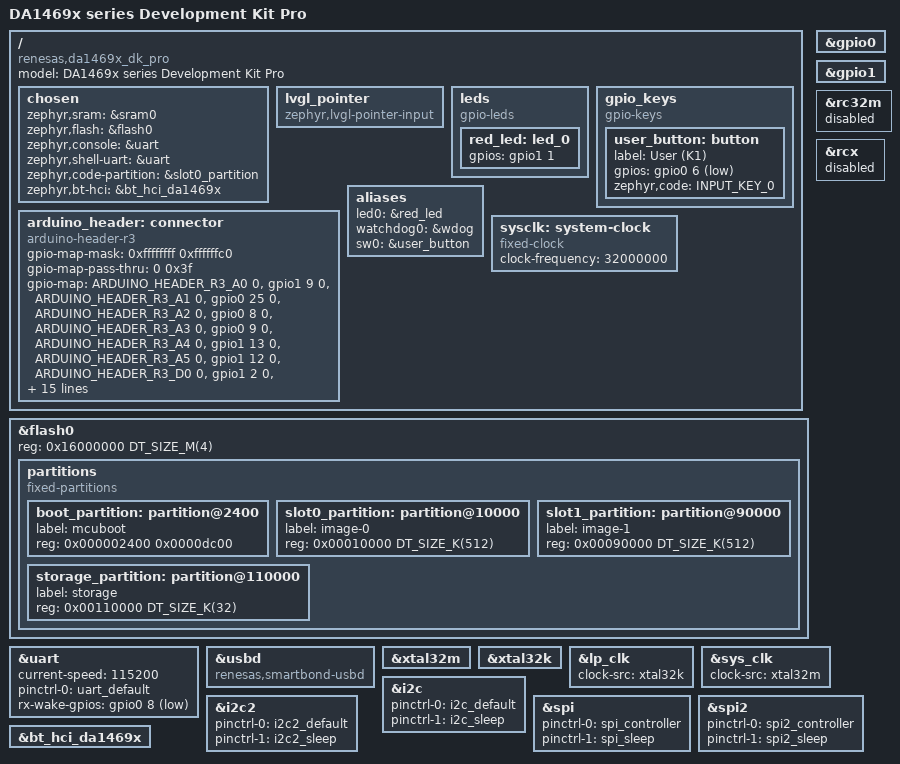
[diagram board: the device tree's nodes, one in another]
/*
 * Copyright (c) 2022 Renesas Electronics Corporation and/or its affiliates
 * SPDX-License-Identifier: Apache-2.0
 */

/dts-v1/;
#include <renesas/smartbond/da14699.dtsi>
#include "da1469x_dk_pro-pinctrl.dtsi"
#include <zephyr/dt-bindings/gpio/arduino-header-r3.h>
#include <zephyr/dt-bindings/input/input-event-codes.h>

/ {
	model = "DA1469x series Development Kit Pro";
	compatible = "renesas,da1469x_dk_pro";
	#address-cells = <1>;
	#size-cells = <1>;

	chosen {
		zephyr,sram = &sram0;
		zephyr,flash = &flash0;
		zephyr,console = &uart;
		zephyr,shell-uart = &uart;
		zephyr,code-partition = &slot0_partition;
		zephyr,bt-hci = &bt_hci_da1469x;
	};

	lvgl_pointer {
		compatible = "zephyr,lvgl-pointer-input";
	};

	leds {
		compatible = "gpio-leds";

		red_led: led_0 {
			gpios = <&gpio1 1 GPIO_ACTIVE_HIGH>;
		};
	};

	gpio_keys {
		compatible = "gpio-keys";

		user_button: button {
			label = "User (K1)";
			gpios = <&gpio0 6 (GPIO_ACTIVE_LOW | GPIO_PULL_UP)>;
			zephyr,code = <INPUT_KEY_0>;
		};
	};

	arduino_header: connector {
		compatible = "arduino-header-r3";
		#gpio-cells = <2>;
		gpio-map-mask = <0xffffffff 0xffffffc0>;
		gpio-map-pass-thru = <0 0x3f>;
		gpio-map = <ARDUINO_HEADER_R3_A0 0 &gpio1 9 0>,
			   <ARDUINO_HEADER_R3_A1 0 &gpio0 25 0>,
			   <ARDUINO_HEADER_R3_A2 0 &gpio0 8 0>,
			   <ARDUINO_HEADER_R3_A3 0 &gpio0 9 0>,
			   <ARDUINO_HEADER_R3_A4 0 &gpio1 13 0>,
			   <ARDUINO_HEADER_R3_A5 0 &gpio1 12 0>,
			   <ARDUINO_HEADER_R3_D0 0 &gpio1 2 0>,
			   <ARDUINO_HEADER_R3_D1 0 &gpio1 3 0>,
			   <ARDUINO_HEADER_R3_D2 0 &gpio1 4 0>,
			   <ARDUINO_HEADER_R3_D3 0 &gpio1 5 0>,
			   <ARDUINO_HEADER_R3_D4 0 &gpio1 7 0>,
			   <ARDUINO_HEADER_R3_D5 0 &gpio1 8 0>,
			   <ARDUINO_HEADER_R3_D6 0 &gpio0 17 0>,
			   <ARDUINO_HEADER_R3_D7 0 &gpio0 18 0>,
			   <ARDUINO_HEADER_R3_D8 0 &gpio0 19 0>,
			   <ARDUINO_HEADER_R3_D9 0 &gpio0 20 0>,
			   <ARDUINO_HEADER_R3_D10 0 &gpio0 21 0>,
			   <ARDUINO_HEADER_R3_D11 0 &gpio0 24 0>,
			   <ARDUINO_HEADER_R3_D12 0 &gpio0 26 0>,
			   <ARDUINO_HEADER_R3_D13 0 &gpio0 27 0>,
			   <ARDUINO_HEADER_R3_D14 0 &gpio0 28 0>,
			   <ARDUINO_HEADER_R3_D15 0 &gpio0 29 0>;
	};

	aliases {
		led0 = &red_led;
		watchdog0 = &wdog;
		sw0 = &user_button;
	};

	sysclk: system-clock {
		compatible = "fixed-clock";
		clock-frequency = <32000000>;
		#clock-cells = <0>;
	};
};

&flash0 {
	reg = <0x16000000 DT_SIZE_M(4)>;

	partitions {
		compatible = "fixed-partitions";
		#address-cells = <1>;
		#size-cells = <1>;

		/*
		 * By default, and due to executing from external flash memories, the I-cache
		 * controller is employed so that no latencies are introduced.
		 * Normally, the controller imposes that image's base address is aligned
		 * to CACHE_FLASH_REG[FLASH_REGION_SIZE], which should reflect image's
		 * size (should be configured on the fly at soc level based on the image size).
		 * The controller should allow for a small offset, up to 0x1000 words,
		 * in case image metadata should be appended.
		 * The current scheme imposes that mcuboot should occupy up to 64kB which is the
		 * minimum cacheable area and then slot0 and slot1 partition entries should follow
		 * without gaps in between.
		 */

		boot_partition: partition@2400 {
			label = "mcuboot";
			reg = <0x000002400 0x0000dc00>;
		};
		slot0_partition: partition@10000 {
			label = "image-0";
			reg = <0x00010000 DT_SIZE_K(512)>;
		};
		slot1_partition: partition@90000 {
			label = "image-1";
			reg = <0x00090000 DT_SIZE_K(512)>;
		};
		storage_partition: partition@110000 {
			label = "storage";
			reg = <0x00110000 DT_SIZE_K(32)>;
		};
	};
};

&gpio0 {
	status = "okay";
};

&gpio1 {
	status = "okay";
};

&uart {
	current-speed = <115200>;
	status = "okay";
	pinctrl-0 = <&uart_default>;
	pinctrl-names = "default";
	rx-wake-gpios = <&gpio0 8 GPIO_ACTIVE_LOW>;
};

zephyr_udc0: &usbd {
	compatible = "renesas,smartbond-usbd";
	status = "okay";
};

&rc32m {
	status = "disabled";
};

&xtal32m {
	status = "okay";
};

&xtal32k {
	status = "okay";
};

/*
 * On board level we switch to XTAL32K and
 * so RCX can be disabled.
 */
&rcx {
	status = "disabled";
};

&lp_clk {
	clock-src = <&xtal32k>;
};

&sys_clk {
	clock-src = <&xtal32m>;
};

&i2c {
	pinctrl-0 = <&i2c_default>;
	pinctrl-1 = <&i2c_sleep>;
	pinctrl-names = "default", "sleep";
};

&i2c2 {
	pinctrl-0 = <&i2c2_default>;
	pinctrl-1 = <&i2c2_sleep>;
	pinctrl-names = "default", "sleep";
};

&spi {
	pinctrl-0 = <&spi_controller>;
	pinctrl-1 = <&spi_sleep>;
	pinctrl-names = "default", "sleep";
};

&spi2 {
	pinctrl-0 = <&spi2_controller>;
	pinctrl-1 = <&spi2_sleep>;
	pinctrl-names = "default", "sleep";
};

&bt_hci_da1469x {
	status = "okay";
};
